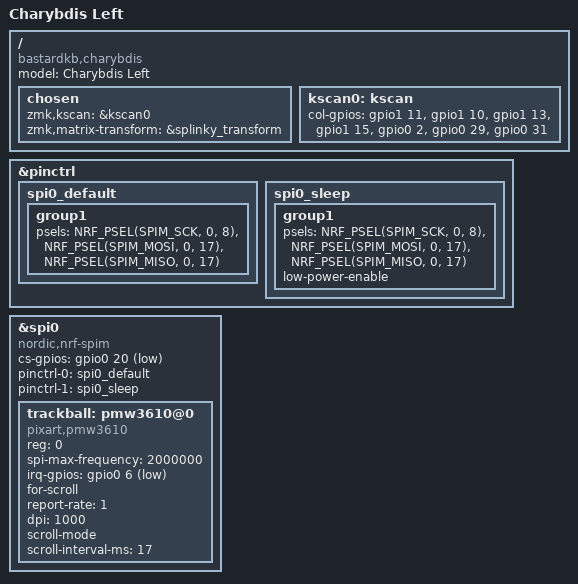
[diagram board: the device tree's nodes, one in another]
/*
 * Copyright (c) 2022 The ZMK Contributors
 *
 * SPDX-License-Identifier: MIT
 */

#include "charybdis.dtsi"

/ {
    model = "Charybdis Left";
    compatible = "bastardkb,charybdis";

    chosen {
        zmk,kscan = &kscan0;
        zmk,matrix-transform = &splinky_transform;
    };

    kscan0: kscan {
        col-gpios
            = <&gpio1 11 GPIO_ACTIVE_HIGH>
            , <&gpio1 10 GPIO_ACTIVE_HIGH>
            , <&gpio1 13 GPIO_ACTIVE_HIGH>
            , <&gpio1 15 GPIO_ACTIVE_HIGH>
            , <&gpio0 2  GPIO_ACTIVE_HIGH>
            , <&gpio0 29 GPIO_ACTIVE_HIGH>
            , <&gpio0 31 GPIO_ACTIVE_HIGH>
            ;
    };
};

&pinctrl {
    spi0_default: spi0_default {
        group1 {
            psels = <NRF_PSEL(SPIM_SCK, 0, 8)>,
                <NRF_PSEL(SPIM_MOSI, 0, 17)>,
                <NRF_PSEL(SPIM_MISO, 0, 17)>;
        };
    };

    spi0_sleep: spi0_sleep {
        group1 {
            psels = <NRF_PSEL(SPIM_SCK, 0, 8)>,
                <NRF_PSEL(SPIM_MOSI, 0, 17)>,
                <NRF_PSEL(SPIM_MISO, 0, 17)>;
            low-power-enable;
        };
    };
};

&spi0 {
    compatible = "nordic,nrf-spim";
    status = "okay";

    cs-gpios = <&gpio0 20 GPIO_ACTIVE_LOW>;

    pinctrl-0 = <&spi0_default>;
    pinctrl-1 = <&spi0_sleep>;
    pinctrl-names = "default", "sleep";

    trackball: pmw3610@0 {
        status = "okay";
        compatible = "pixart,pmw3610";
        reg = <0>;
        spi-max-frequency = <2000000>;
        irq-gpios = <&gpio0 6 (GPIO_ACTIVE_LOW | GPIO_PULL_UP)>;

        /* Use the scroll behavior */
        for-scroll;
        report-rate = <1>; /* 0: 125Hz, 1: 250Hz, 2: 500Hz, 3: 1000Hz */
        dpi = <1000>; /* Supported dpi values: 125, 250, 500, 1000, 1250, 1500, 1750, 2000 */
        scroll-mode;
        scroll-interval-ms = <17>;
    };
};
